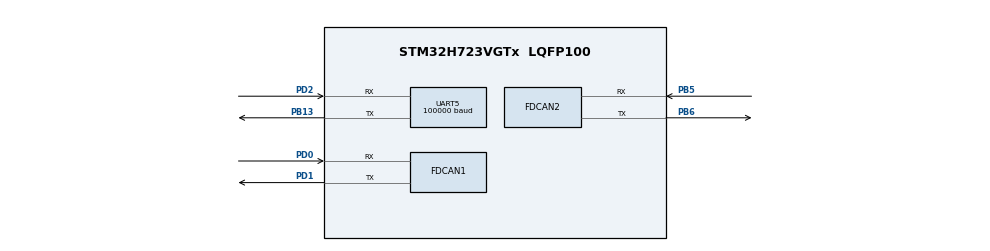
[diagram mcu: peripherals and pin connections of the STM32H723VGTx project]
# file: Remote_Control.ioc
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Dma.Request0=UART5_RX
Dma.UART5_RX.0.Direction=DMA_PERIPH_TO_MEMORY
Dma.UART5_RX.0.EventEnable=DISABLE
Dma.UART5_RX.0.FIFOMode=DMA_FIFOMODE_DISABLE
Dma.UART5_RX.0.Instance=DMA1_Stream0
Dma.UART5_RX.0.MemDataAlignment=DMA_MDATAALIGN_BYTE
Dma.UART5_RX.0.MemInc=DMA_MINC_ENABLE
Dma.UART5_RX.0.Mode=DMA_NORMAL
Dma.UART5_RX.0.PeriphDataAlignment=DMA_PDATAALIGN_BYTE
Dma.UART5_RX.0.PeriphInc=DMA_PINC_DISABLE
Dma.UART5_RX.0.Polarity=HAL_DMAMUX_REQ_GEN_RISING
Dma.UART5_RX.0.Priority=DMA_PRIORITY_VERY_HIGH
Dma.UART5_RX.0.RequestNumber=1
Dma.UART5_RX.0.SignalID=NONE
Dma.UART5_RX.0.SyncEnable=DISABLE
Dma.UART5_RX.0.SyncPolarity=HAL_DMAMUX_SYNC_NO_EVENT
Dma.UART5_RX.0.SyncRequestNumber=1
Dma.UART5_RX.0.SyncSignalID=NONE
FDCAN1.AutoRetransmission=ENABLE
FDCAN1.CalculateBaudRateNominal=1000000
FDCAN1.CalculateTimeBitNominal=1000
FDCAN1.CalculateTimeQuantumNominal=50.0
FDCAN1.MessageRAMOffset=0x400
FDCAN1.NominalPrescaler=4
FDCAN1.NominalTimeSeg1=15
FDCAN1.NominalTimeSeg2=4
FDCAN1.RxFifo0ElmtsNbr=16
FDCAN1.StdFiltersNbr=2
FDCAN1.TxFifoQueueElmtsNbr=3
FDCAN2.AutoRetransmission=ENABLE
FDCAN2.CalculateBaudRateNominal=1000000
FDCAN2.CalculateTimeBitNominal=1000
FDCAN2.CalculateTimeQuantumNominal=50.0
FDCAN2.NominalPrescaler=4
FDCAN2.NominalTimeSeg1=15
FDCAN2.NominalTimeSeg2=4
FDCAN2.RxFifo0ElmtsNbr=16
FDCAN2.RxFifo1ElmtsNbr=3
FDCAN2.StdFiltersNbr=2
FDCAN2.TxFifoQueueElmtsNbr=3
Mcu.Family=STM32H7
Mcu.Name=STM32H723VGTx
Mcu.Package=LQFP100
NVIC.DMA1_Stream0_IRQn=true\:1\:0\:true\:false\:true\:false\:true\:true
NVIC.FDCAN1_IT0_IRQn=true\:0\:0\:false\:false\:true\:true\:true\:true
NVIC.FDCAN2_IT0_IRQn=true\:2\:0\:true\:false\:true\:true\:true\:true
NVIC.PriorityGroup=NVIC_PRIORITYGROUP_4
NVIC.UART5_IRQn=true\:1\:0\:true\:false\:true\:true\:true\:true
PA13(JTMS/SWDIO).Mode=Serial_Wire
PA13(JTMS/SWDIO).Signal=DEBUG_JTMS-SWDIO
PA14(JTCK/SWCLK).Mode=Serial_Wire
PA14(JTCK/SWCLK).Signal=DEBUG_JTCK-SWCLK
PB13.Mode=Asynchronous
PB13.Signal=UART5_TX
PB5.Mode=FDCAN_Activate
PB5.Signal=FDCAN2_RX
PB6.Mode=FDCAN_Activate
PB6.Signal=FDCAN2_TX
PD0.Mode=FDCAN_Activate
PD0.Signal=FDCAN1_RX
PD1.Mode=FDCAN_Activate
PD1.Signal=FDCAN1_TX
PD2.Mode=Asynchronous
PD2.Signal=UART5_RX
PH0-OSC_IN.Mode=HSE-External-Oscillator
PH0-OSC_IN.Signal=RCC_OSC_IN
PH1-OSC_OUT.Mode=HSE-External-Oscillator
PH1-OSC_OUT.Signal=RCC_OSC_OUT
ProjectManager.HeapSize=0x200
ProjectManager.StackSize=0x400
ProjectManager.TargetToolchain=Makefile
RCC.ADCFreq_Value=160000000
RCC.APB1Freq_Value=132000000
RCC.APB2Freq_Value=132000000
RCC.APB3Freq_Value=132000000
RCC.APB4Freq_Value=132000000
RCC.CortexFreq_Value=528000000
RCC.D1PPRE=RCC_APB3_DIV2
RCC.D2PPRE1=RCC_APB1_DIV2
RCC.D2PPRE2=RCC_APB2_DIV2
RCC.D3PPRE=RCC_APB4_DIV2
RCC.DIVM1=5
RCC.DIVM2=3
RCC.DIVN1=110
RCC.DIVN2=40
RCC.DIVP1=1
RCC.DIVQ2=4
RCC.FDCANCLockSelection=RCC_FDCANCLKSOURCE_PLL2
RCC.HCLKFreq_Value=264000000
RCC.HPRE=RCC_HCLK_DIV2
RCC.HSE_VALUE=24000000
RCC.PLLSourceVirtual=RCC_PLLSOURCE_HSE
RCC.SYSCLKFreq_VALUE=528000000
RCC.SYSCLKSource=RCC_SYSCLKSOURCE_PLLCLK
RCC.USBFreq_Value=264000000
UART5.BaudRate=100000
UART5.Parity=PARITY_EVEN
UART5.StopBits=UART_STOPBITS_2
UART5.WordLength=WORDLENGTH_9B
VP_MEMORYMAP_VS_MEMORYMAP.Mode=CurAppReg
board=custom

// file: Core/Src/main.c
/* USER CODE BEGIN Header */
/**
  ******************************************************************************
  * @file           : main.c
  * @brief          : Main program body
  ******************************************************************************
  * @attention
  *
  * Copyright (c) 2026 STMicroelectronics.
  * All rights reserved.
  *
  * This software is licensed under terms that can be found in the LICENSE file
  * in the root directory of this software component.
  * If no LICENSE file comes with this software, it is provided AS-IS.
  *
  ******************************************************************************
  */
/* USER CODE END Header */
#include "main.h"
#include "dma.h"
#include "fdcan.h"
#include "usart.h"
#include "gpio.h"

/* USER CODE BEGIN Includes */
#include "DJ_Motor.h"
#include "rc_dbus.h"
#include "mecanum.h"
#include "bsp.can.h"
/* USER CODE END Includes */

void SystemClock_Config(void);
void PeriphCommonClock_Config(void);

int main(void)
{

  /* MCU Configuration--------------------------------------------------------*/

  /* Reset of all peripherals, Initializes the Flash interface and the Systick. */
  HAL_Init();

  /* Configure the system clock */
  SystemClock_Config();

  /* Configure the peripherals common clocks */
  PeriphCommonClock_Config();

  /* Initialize all configured peripherals */
  MX_GPIO_Init();
  MX_DMA_Init();
  MX_FDCAN2_Init();
  MX_UART5_Init();
  MX_FDCAN1_Init();
  /* USER CODE BEGIN 2 */
  FDCAN2_Start();        /* CAN2：底盘左/右 + 云台 yaw */
  FDCAN1_Start();        /* CAN1：摩擦轮 + 云台 pitch */
  RC_Init();             /* 启动 DBUS(UART5) 接收 */
  /* USER CODE END 2 */

  /* Infinite loop */
  /* USER CODE BEGIN WHILE */
uint32_t rc_last_tick = 0;
while (1) {
  /*约1ms调用一次*/
    uint32_t now = HAL_GetTick();
    if ((int32_t)(now - rc_last_tick) >= 1) {   /* ~1ms, 匹配 mecanum 1kHz 斜坡 */
        rc_last_tick = now;
        RC_Control_Task();
    }
   //DJ3508_Send_I_Can2(1000,1000,1000,1000);
    /* USER CODE END WHILE */

}
}

void SystemClock_Config(void)
{
  RCC_OscInitTypeDef RCC_OscInitStruct = {0};
  RCC_ClkInitTypeDef RCC_ClkInitStruct = {0};

  /** Supply configuration update enable
  */
  HAL_PWREx_ConfigSupply(PWR_LDO_SUPPLY);

  /** Configure the main internal regulator output voltage
  */
  __HAL_PWR_VOLTAGESCALING_CONFIG(PWR_REGULATOR_VOLTAGE_SCALE0);

  while(!__HAL_PWR_GET_FLAG(PWR_FLAG_VOSRDY)) {}

  /** Initializes the RCC Oscillators according to the specified parameters
  * in the RCC_OscInitTypeDef structure.
  */
  RCC_OscInitStruct.OscillatorType = RCC_OSCILLATORTYPE_HSE;
  RCC_OscInitStruct.HSEState = RCC_HSE_ON;
  RCC_OscInitStruct.PLL.PLLState = RCC_PLL_ON;
  RCC_OscInitStruct.PLL.PLLSource = RCC_PLLSOURCE_HSE;
  RCC_OscInitStruct.PLL.PLLM = 5;
  RCC_OscInitStruct.PLL.PLLN = 110;
  RCC_OscInitStruct.PLL.PLLP = 1;
  RCC_OscInitStruct.PLL.PLLQ = 2;
  RCC_OscInitStruct.PLL.PLLR = 2;
  RCC_OscInitStruct.PLL.PLLRGE = RCC_PLL1VCIRANGE_2;
  RCC_OscInitStruct.PLL.PLLVCOSEL = RCC_PLL1VCOWIDE;
  RCC_OscInitStruct.PLL.PLLFRACN = 0;
  if (HAL_RCC_OscConfig(&RCC_OscInitStruct) != HAL_OK)
  {
    Error_Handler();
  }

  /** Initializes the CPU, AHB and APB buses clocks
  */
  RCC_ClkInitStruct.ClockType = RCC_CLOCKTYPE_HCLK|RCC_CLOCKTYPE_SYSCLK
                              |RCC_CLOCKTYPE_PCLK1|RCC_CLOCKTYPE_PCLK2
                              |RCC_CLOCKTYPE_D3PCLK1|RCC_CLOCKTYPE_D1PCLK1;
  RCC_ClkInitStruct.SYSCLKSource = RCC_SYSCLKSOURCE_PLLCLK;
  RCC_ClkInitStruct.SYSCLKDivider = RCC_SYSCLK_DIV1;
  RCC_ClkInitStruct.AHBCLKDivider = RCC_HCLK_DIV2;
  RCC_ClkInitStruct.APB3CLKDivider = RCC_APB3_DIV2;
  RCC_ClkInitStruct.APB1CLKDivider = RCC_APB1_DIV2;
  RCC_ClkInitStruct.APB2CLKDivider = RCC_APB2_DIV2;
  RCC_ClkInitStruct.APB4CLKDivider = RCC_APB4_DIV2;

  if (HAL_RCC_ClockConfig(&RCC_ClkInitStruct, FLASH_LATENCY_3) != HAL_OK)
  {
    Error_Handler();
  }
}

void PeriphCommonClock_Config(void)
{
  RCC_PeriphCLKInitTypeDef PeriphClkInitStruct = {0};

  /** Initializes the peripherals clock
  */
  PeriphClkInitStruct.PeriphClockSelection = RCC_PERIPHCLK_FDCAN;
  PeriphClkInitStruct.PLL2.PLL2M = 3;
  PeriphClkInitStruct.PLL2.PLL2N = 40;
  PeriphClkInitStruct.PLL2.PLL2P = 2;
  PeriphClkInitStruct.PLL2.PLL2Q = 4;
  PeriphClkInitStruct.PLL2.PLL2R = 2;
  PeriphClkInitStruct.PLL2.PLL2RGE = RCC_PLL2VCIRANGE_3;
  PeriphClkInitStruct.PLL2.PLL2VCOSEL = RCC_PLL2VCOWIDE;
  PeriphClkInitStruct.PLL2.PLL2FRACN = 0;
  PeriphClkInitStruct.FdcanClockSelection = RCC_FDCANCLKSOURCE_PLL2;
  if (HAL_RCCEx_PeriphCLKConfig(&PeriphClkInitStruct) != HAL_OK)
  {
    Error_Handler();
  }
}

void Error_Handler(void)
{
  __disable_irq();
  while (1)
  {
  }
}
